# GD32F20x_CL register map
File version: 1.0
CPU: CM3 r2p1, little endian, no MPU, no FPU, 4 interrupt priority bits
Registers are 32-bit, read-write, reset 0x0 unless marked. A register's access mark holds for its fields unless they carry their own. Offsets are from the block's base; [hi:lo] are bit positions; 'fields as' and 'values as' point back to an identical list.

## TLI — TFT-LCD interface
Base 0x40016800
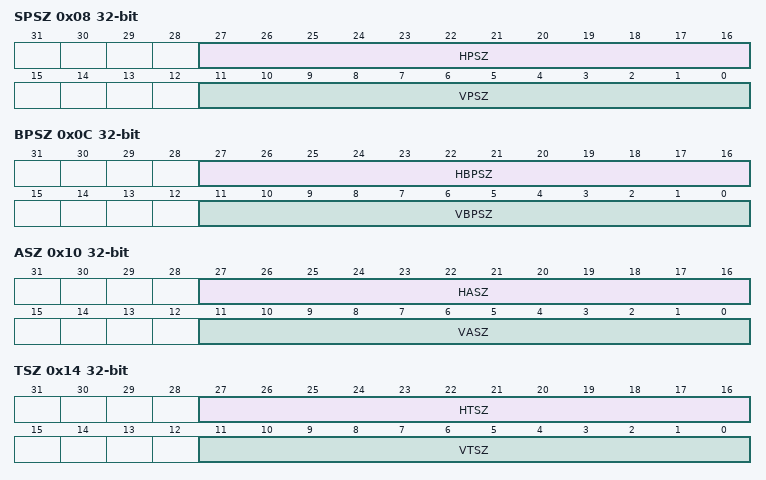
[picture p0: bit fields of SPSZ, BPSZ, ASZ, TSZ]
0x08 SPSZ — Synchronous pulse size register
  [27:16] HPSZ — size of horizontal synchronous pluse
  [11:0] VPSZ — size of vertical synchronous pluse
0x0C BPSZ — Back-porch size register
  [27:16] HBPSZ — Size of the horizontal back porch plus synchronous pulse
  [11:0] VBPSZ — Size of the vertical back porch plus synchronous pulse
0x10 ASZ — Active size register
  [27:16] HASZ — Size of the horizontal active area width plus back porch and synchronous pulse
  [11:0] VASZ — Size of the vertical active area width plus back porch and synchronous pulse
0x14 TSZ — Total size register
  [27:16] HTSZ — Horizontal total size of the display
  [11:0] VTSZ — Vertical total size of the display
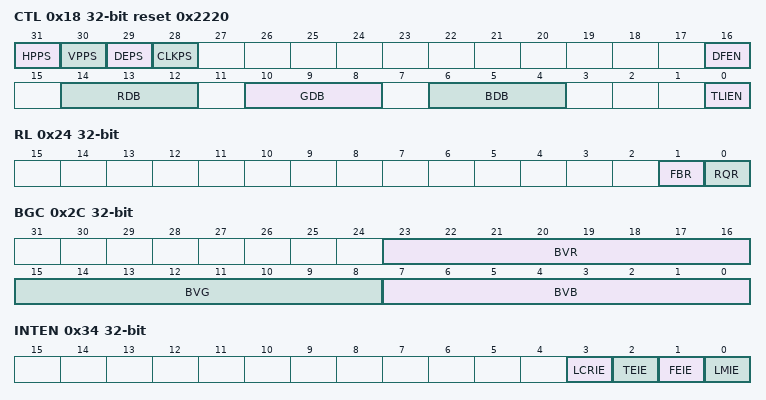
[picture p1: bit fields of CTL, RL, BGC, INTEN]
0x18 CTL access per field reset 0x2220 — Control register
  [31] HPPS rw — Horizontal Pulse Polarity Selection
  [30] VPPS rw — Vertical Pulse Polarity Selection
  [29] DEPS rw — Data Enable Polarity Selection
  [28] CLKPS rw — Pixel Clock Polarity Selection
  [16] DFEN rw — Dither Function Enable
  [14:12] RDB ro — Red channel Dither Bits Number
  [10:8] GDB ro — Green channel Dither Bits Number
  [6:4] BDB ro — Blue channel Dither Bits Number
  [0] TLIEN rw — TLI enable bit
0x24 RL — Reload layer register
  [1] FBR — Frame Blank Reload
  [0] RQR — Request Reload
0x2C BGC — Background color register
  [23:16] BVR — Background value red
  [15:8] BVG — Background value green
  [7:0] BVB — Background value blue
0x34 INTEN — Interrupt enable register
  [3] LCRIE — Layer Configuration Reloaded Interrupt Enable
  [2] TEIE — Transaction Error Interrupt Enable
  [1] FEIE — FIFO Error Interrupt Enable
  [0] LMIE — Line Mark Interrupt Enable
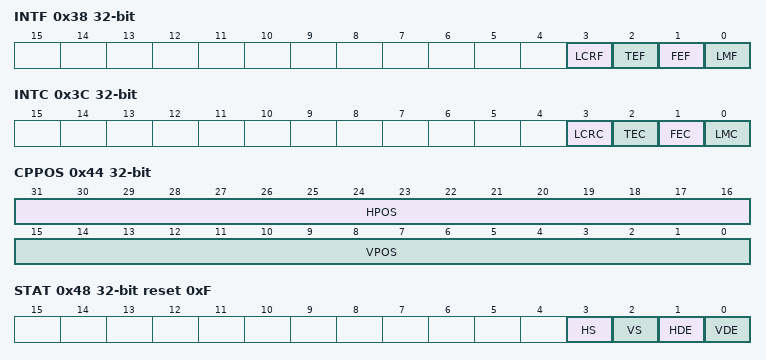
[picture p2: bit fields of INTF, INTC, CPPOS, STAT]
0x38 INTF ro — Interrupt flag register
  [3] LCRF — Layer Configuration Reloaded Flag
  [2] TEF — Transaction Error Flag
  [1] FEF — FIFO Error Flag
  [0] LMF — Line Mark Flag
0x3C INTC wo — Interrupt flag clear register
  [3] LCRC — Layer Configuration Reloaded Flag Clear
  [2] TEC — Transaction Error Flag Clear
  [1] FEC — FIFO Error Flag Clear
  [0] LMC — Line Mark Flag Clear
0x40 LM — Line mark register
  [10:0] LM — Line Mark value
0x44 CPPOS ro — Current pixel position register
  [31:16] HPOS — Horizontal position
  [15:0] VPOS — Vertical position
0x48 STAT ro reset 0xF — Status register
  [3] HS — Current HS staus of the TLI
  [2] VS — Current VS staus of the TLI
  [1] HDE — Current HDE status
  [0] VDE — Current VDE status
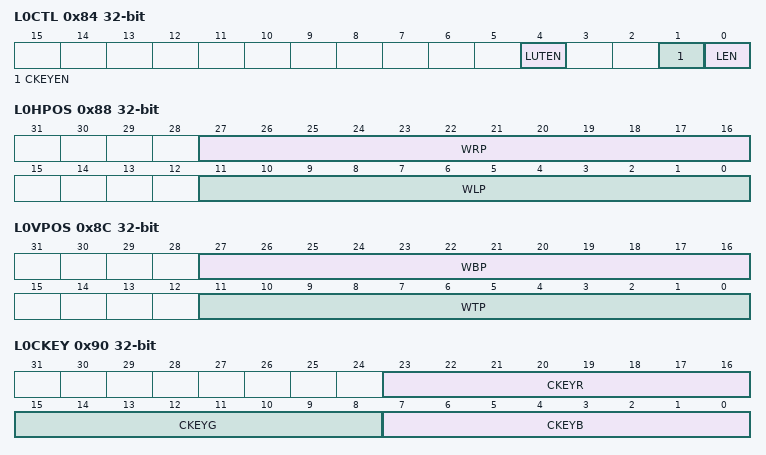
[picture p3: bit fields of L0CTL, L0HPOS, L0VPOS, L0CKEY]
0x84 L0CTL — Layer 0 control register
  [4] LUTEN — LUT enable
  [1] CKEYEN — Color keying enable
  [0] LEN — Layer enable
0x88 L0HPOS — Layer 0 horizontal position parameters register
  [27:16] WRP — Window right position
  [11:0] WLP — Window left position
0x8C L0VPOS — Layer 0 vertical position parameters register
  [27:16] WBP — Window bottom position
  [11:0] WTP — Window top position
0x90 L0CKEY — Layer 0 color key register
  [23:16] CKEYR — Color Key Red
  [15:8] CKEYG — Color Key Green
  [7:0] CKEYB — Color Key Blue
0x94 L0PPF — Layer 0 packeted pixel format register
  [2:0] PPF — Packeted Pixel Format
0x98 L0SA reset 0xFF — Layer 0 specified alpha register
  [7:0] SA — Specified alpha
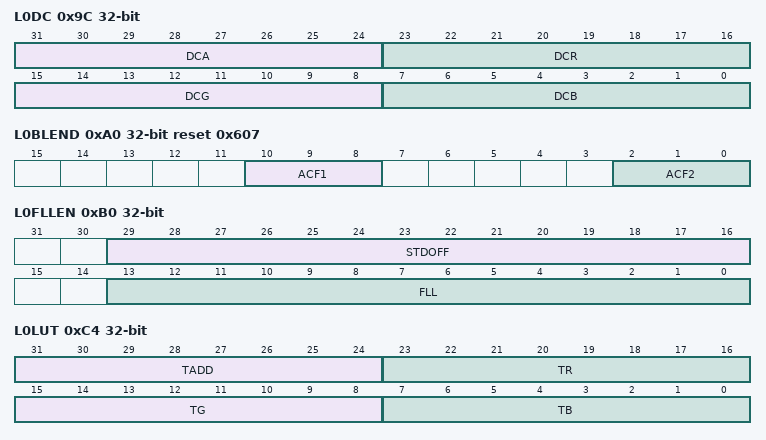
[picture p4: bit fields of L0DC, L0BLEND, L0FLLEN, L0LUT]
0x9C L0DC — Layer 0 default color register
  [31:24] DCA — The default color ALPHA
  [23:16] DCR — The default color red
  [15:8] DCG — The default color green
  [7:0] DCB — The default color blue
0xA0 L0BLEND reset 0x607 — Layer 0 blending register
  [10:8] ACF1 — Alpha Calculation Factor 1 of Blending Method
  [2:0] ACF2 — Alpha Calculation Factor 2 of Blending Method
0xAC L0FBADDR — Layer 0 frame base address register
  [31:0] FBADD — Frame Buffer base Address
0xB0 L0FLLEN — Layer 0 frame line length register
  [29:16] STDOFF — Frame Buffer Stride Offset
  [13:0] FLL — Frame Line Length
0xB4 L0FTLN — Layer 0 frame total line number register
  [10:0] FTLN — Frame Total Line Number
0xC4 L0LUT wo — Layer 0 look up table register
  [31:24] TADD — Look Up Table Write Address
  [23:16] TR — Red Channel of a LUT entry
  [15:8] TG — Green channel of a LUT entry
  [7:0] TB — Blue channel of a LUT entry
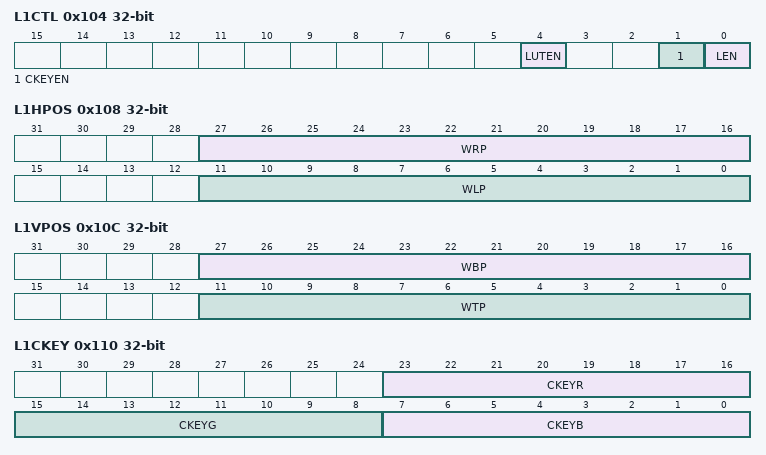
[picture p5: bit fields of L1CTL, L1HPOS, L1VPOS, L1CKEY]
0x104 L1CTL — Layer 1 control register
  fields as L0CTL
0x108 L1HPOS — Layer 1 horizontal position parameters register
  fields as L0HPOS
0x10C L1VPOS — Layer 1 vertical position parameters register
  fields as L0VPOS
0x110 L1CKEY — Layer 1 color key register
  fields as L0CKEY
0x114 L1PPF — Layer 1 packeted pixel format register
  [2:0] PPF — Packeted Pixel Format
0x118 L1SA reset 0xFF — Layer 1 specified alpha register
  [7:0] SA — Specified alpha
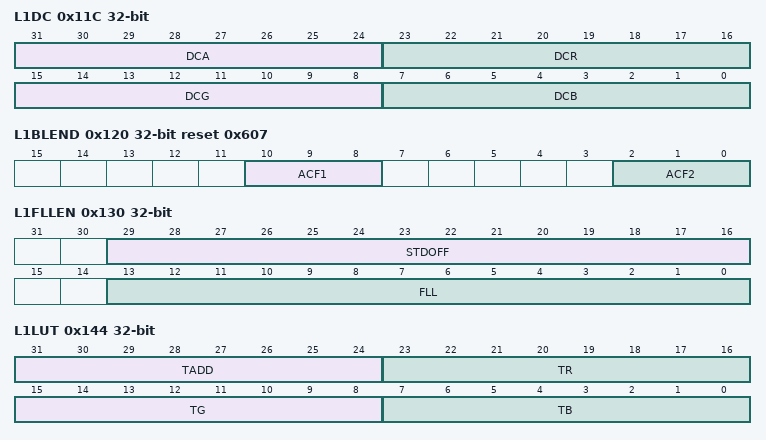
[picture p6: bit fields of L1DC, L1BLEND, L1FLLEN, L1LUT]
0x11C L1DC — Layer 1 default color register
  fields as L0DC
0x120 L1BLEND reset 0x607 — Layer 1 blending register
  fields as L0BLEND
0x12C L1FBADDR — Layer 1 frame base address register
  [31:0] FBADD — Frame Buffer base Address
0x130 L1FLLEN — Layer 1 frame line length register
  fields as L0FLLEN
0x134 L1FTLN — Layer 1 frame total line number register
  [10:0] FTLN — Frame Total Line Number
0x144 L1LUT wo — Layer 1 look up table register
  [31:24] TADD — Look Up Table Write Address
  [23:16] TR — Red channel of a LUT entry
  [15:8] TG — Green channel of a LUT entry
  [7:0] TB — Blue channel of a LUT entry
